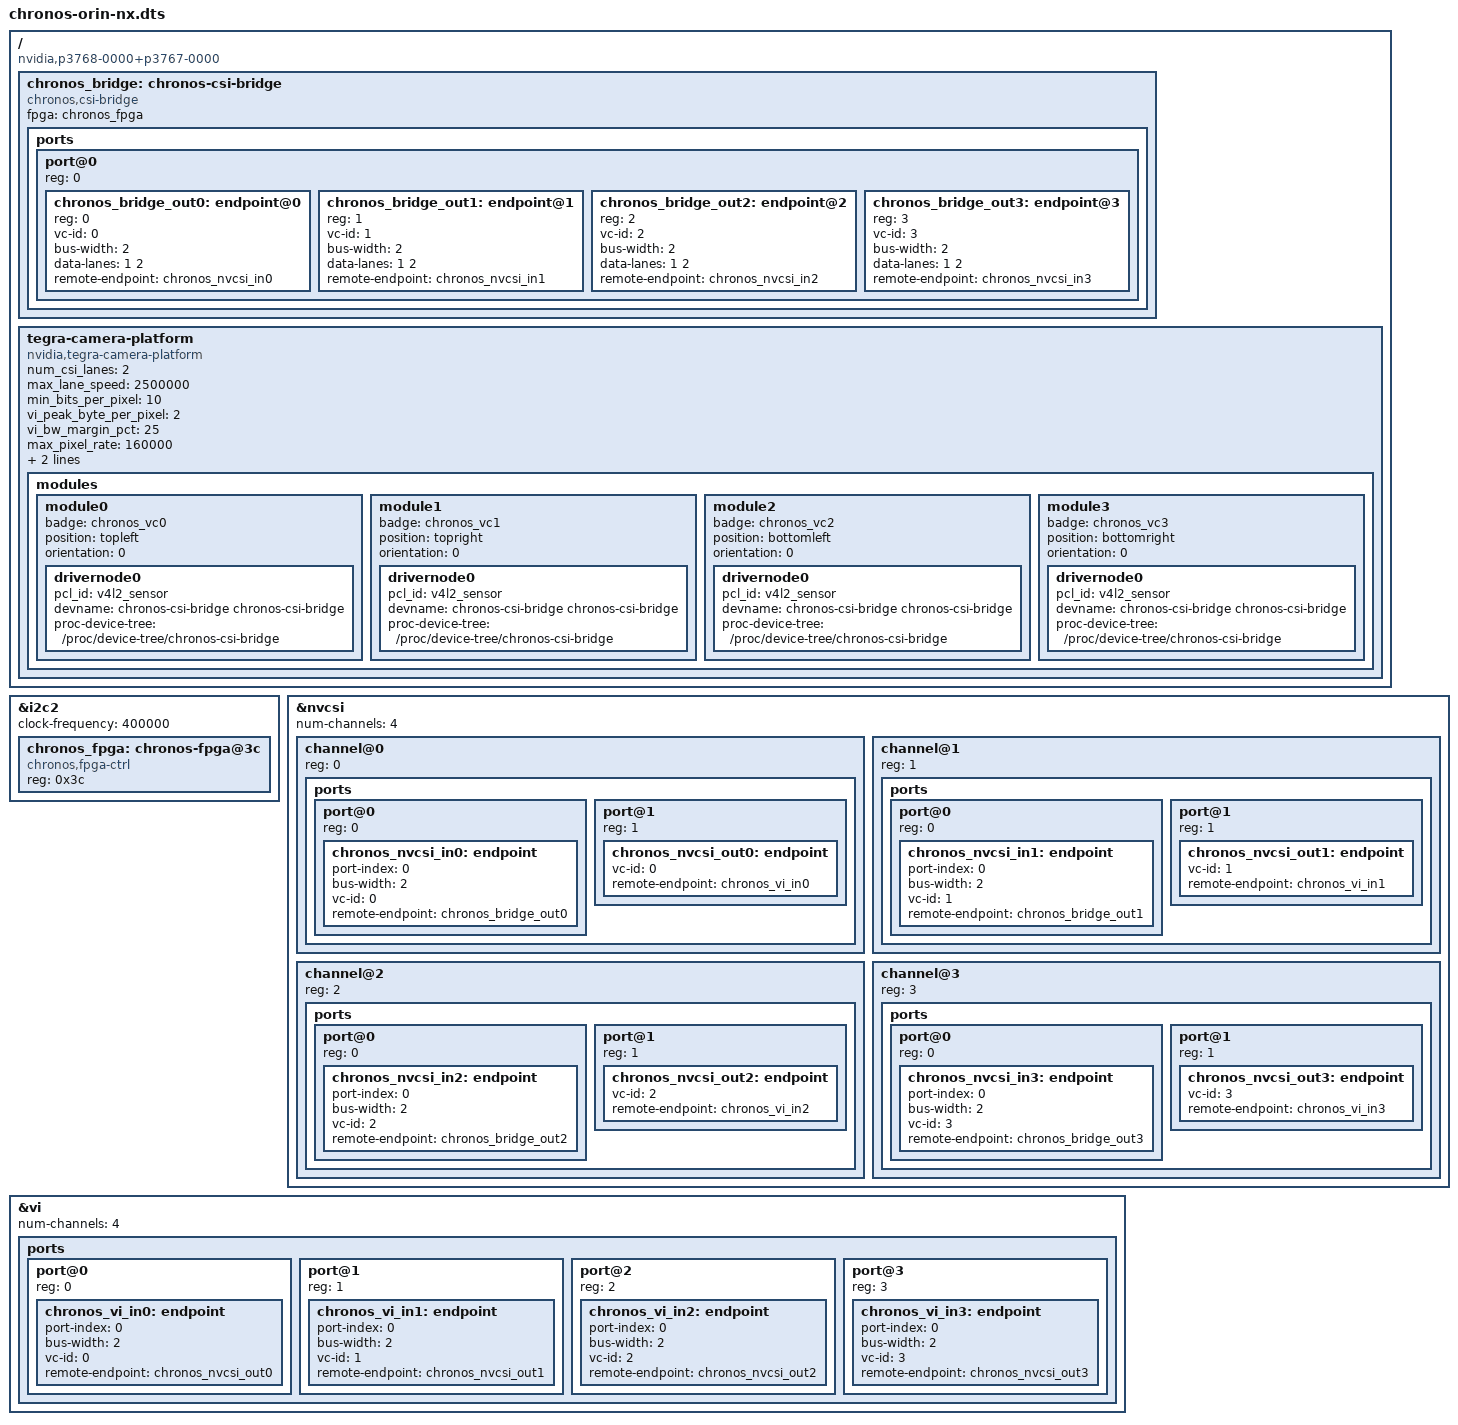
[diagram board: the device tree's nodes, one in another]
// SPDX-License-Identifier: GPL-2.0-only
/*
 * Chronos multi-camera board - device tree overlay for NVIDIA Jetson Orin NX.
 *
 * Board reference : HW_CHRONOS_R1
 *
 * REAL architecture (source of truth: FPGA RTL + board netlist):
 *
 *   - A Lattice CrossLink-NX FPGA aggregates 4x OV9281 cameras into ONE
 *     2-lane MIPI CSI-2 link to the Jetson (connector J7), using virtual
 *     channels VC0..VC3 (VC = camera index).  The Jetson sees exactly one
 *     2-lane CSI source: RAW10 monochrome, 1280x800, 30 fps design point,
 *     frames hardware-triggered by the FPGA FSIN generator.
 *
 *   - The Jetson CANNOT reach the OV9281 sensors over I2C.  The FPGA owns
 *     per-camera private SCCB buses and configures the sensors itself.
 *     There is no I2C mux and there are no sensor nodes in this overlay.
 *
 *   - The FPGA forwards a single on-board 27 MHz oscillator to all four
 *     camera XCLK inputs (the camera modules have no oscillator of their
 *     own).  No clock is modelled on the Jetson side.
 *
 *   - The ICM-42688-P IMU is wired ONLY to the FPGA (SPI + INT).  The
 *     Jetson has no path to it, so it does not appear in this overlay.
 *
 *   - The only Jetson-visible control interface is the FPGA I2C slave at
 *     7-bit address 0x3C (register map in fpga/rtl/config_regs.sv),
 *     handled by the chronos_fpga driver.
 *
 * Driver topology created by this overlay:
 *
 *   chronos_fpga (I2C 0x3C)  <--fpga phandle--  chronos_bridge (subdev)
 *                                                     | x4 endpoints
 *                                             NVCSI channel@0..3
 *                                                     | 1:1
 *                                             VI (4 channels, vc-id 0..3)
 *
 * The Tegra VI creates /dev/video0..3; all four map to the same physical
 * 2-lane NVCSI stream and are demultiplexed by virtual channel (the graph
 * is fanned out 1:1 bridge-endpoint -> NVCSI channel -> VI port because
 * Tegra requires strict endpoint pairing, as in L4T GMSL examples).
 */

/dts-v1/;
/plugin/;

/ {
	compatible = "nvidia,p3768-0000+p3767-0000";  /* Orin NX dev kit */

	/* Host I2C2 -> FPGA control interface (7-bit 0x3C). */
	fragment@0 {
		target = <&i2c2>;
		__overlay__ {
			#address-cells = <1>;
			#size-cells = <0>;
			status = "okay";
			clock-frequency = <400000>;

			chronos_fpga: chronos-fpga@3c {
				compatible = "chronos,fpga-ctrl";
				reg = <0x3c>;
				status = "okay";
			};
		};
	};

	/*
	 * The aggregated CSI-2 source.  One subdev with one source port that
	 * carries FOUR endpoints - one per virtual channel - because Tegra's
	 * multi-VC plumbing (same mechanism as L4T GMSL setups) requires a
	 * strict 1:1 endpoint pairing all the way down the graph:
	 *   bridge endpoint@N  <->  NVCSI channel@N input,
	 *   NVCSI channel@N output  <->  VI port@N.
	 * All four share the SAME physical 2-lane link; only the vc-id
	 * differs.
	 */
	fragment@1 {
		target-path = "/";
		__overlay__ {
			chronos_bridge: chronos-csi-bridge {
				compatible = "chronos,csi-bridge";
				status = "okay";

				fpga = <&chronos_fpga>;

				ports {
					#address-cells = <1>;
					#size-cells = <0>;

					port@0 {
						reg = <0>;
						#address-cells = <1>;
						#size-cells = <0>;

						chronos_bridge_out0: endpoint@0 {
							reg = <0>;
							vc-id = <0>;
							bus-width = <2>;
							data-lanes = <1 2>;
							remote-endpoint = <&chronos_nvcsi_in0>;
						};
						chronos_bridge_out1: endpoint@1 {
							reg = <1>;
							vc-id = <1>;
							bus-width = <2>;
							data-lanes = <1 2>;
							remote-endpoint = <&chronos_nvcsi_in1>;
						};
						chronos_bridge_out2: endpoint@2 {
							reg = <2>;
							vc-id = <2>;
							bus-width = <2>;
							data-lanes = <1 2>;
							remote-endpoint = <&chronos_nvcsi_in2>;
						};
						chronos_bridge_out3: endpoint@3 {
							reg = <3>;
							vc-id = <3>;
							bus-width = <2>;
							data-lanes = <1 2>;
							remote-endpoint = <&chronos_nvcsi_in3>;
						};
					};
				};
			};
		};
	};

	/*
	 * NVCSI: four channels (matching VI num-channels), all on physical
	 * port A / brick 0, one per virtual channel.  Every channel input
	 * pairs 1:1 with a bridge endpoint and every output with a VI port.
	 */
	fragment@2 {
		target = <&nvcsi>;
		__overlay__ {
			status = "okay";
			num-channels = <4>;
			#address-cells = <1>;
			#size-cells = <0>;

			channel@0 {
				reg = <0>;
				status = "okay";

				ports {
					#address-cells = <1>;
					#size-cells = <0>;

					port@0 {
						reg = <0>;
						chronos_nvcsi_in0: endpoint {
							port-index = <0>;
							bus-width = <2>;
							vc-id = <0>;
							remote-endpoint = <&chronos_bridge_out0>;
						};
					};
					port@1 {
						reg = <1>;
						chronos_nvcsi_out0: endpoint {
							vc-id = <0>;
							remote-endpoint = <&chronos_vi_in0>;
						};
					};
				};
			};

			channel@1 {
				reg = <1>;
				status = "okay";

				ports {
					#address-cells = <1>;
					#size-cells = <0>;

					port@0 {
						reg = <0>;
						chronos_nvcsi_in1: endpoint {
							port-index = <0>;
							bus-width = <2>;
							vc-id = <1>;
							remote-endpoint = <&chronos_bridge_out1>;
						};
					};
					port@1 {
						reg = <1>;
						chronos_nvcsi_out1: endpoint {
							vc-id = <1>;
							remote-endpoint = <&chronos_vi_in1>;
						};
					};
				};
			};

			channel@2 {
				reg = <2>;
				status = "okay";

				ports {
					#address-cells = <1>;
					#size-cells = <0>;

					port@0 {
						reg = <0>;
						chronos_nvcsi_in2: endpoint {
							port-index = <0>;
							bus-width = <2>;
							vc-id = <2>;
							remote-endpoint = <&chronos_bridge_out2>;
						};
					};
					port@1 {
						reg = <1>;
						chronos_nvcsi_out2: endpoint {
							vc-id = <2>;
							remote-endpoint = <&chronos_vi_in2>;
						};
					};
				};
			};

			channel@3 {
				reg = <3>;
				status = "okay";

				ports {
					#address-cells = <1>;
					#size-cells = <0>;

					port@0 {
						reg = <0>;
						chronos_nvcsi_in3: endpoint {
							port-index = <0>;
							bus-width = <2>;
							vc-id = <3>;
							remote-endpoint = <&chronos_bridge_out3>;
						};
					};
					port@1 {
						reg = <1>;
						chronos_nvcsi_out3: endpoint {
							vc-id = <3>;
							remote-endpoint = <&chronos_vi_in3>;
						};
					};
				};
			};
		};
	};

	/*
	 * VI: four channels, all mapped to the SAME NVCSI physical stream,
	 * selected by CSI-2 virtual channel via the "vc-id" endpoint property
	 * (same mechanism L4T uses for multi-VC GMSL setups).  VC = camera
	 * index.  VI allocates capture buffers from CMA; no reserved-memory
	 * carveout is needed.
	 */
	fragment@3 {
		target = <&vi>;
		__overlay__ {
			status = "okay";
			num-channels = <4>;

			ports {
				#address-cells = <1>;
				#size-cells = <0>;

				port@0 {
					reg = <0>;
					chronos_vi_in0: endpoint {
						port-index = <0>;
						bus-width = <2>;
						vc-id = <0>;
						remote-endpoint = <&chronos_nvcsi_out0>;
					};
				};
				port@1 {
					reg = <1>;
					chronos_vi_in1: endpoint {
						port-index = <0>;
						bus-width = <2>;
						vc-id = <1>;
						remote-endpoint = <&chronos_nvcsi_out1>;
					};
				};
				port@2 {
					reg = <2>;
					chronos_vi_in2: endpoint {
						port-index = <0>;
						bus-width = <2>;
						vc-id = <2>;
						remote-endpoint = <&chronos_nvcsi_out2>;
					};
				};
				port@3 {
					reg = <3>;
					chronos_vi_in3: endpoint {
						port-index = <0>;
						bus-width = <2>;
						vc-id = <3>;
						remote-endpoint = <&chronos_nvcsi_out3>;
					};
				};
			};
		};
	};

	/*
	 * tegra-camera-platform: one module entry per virtual channel so the
	 * Tegra camera framework sizes clocks/bandwidth for four streams.
	 *
	 * Entries are intentionally minimal and honest: the "sensor" of this
	 * graph is the Chronos bridge (there are no Jetson-visible OV9281
	 * devices).  Argus/nvarguscamerasrc additionally requires per-mode
	 * tables (mode0 { ... }) matching the sensor timing before it will
	 * use these modules; V4L2 capture via v4l2-ctl works without them.
	 *
	 * NOTE: drivernode0 must reference the V4L2 subdev that sources the
	 * stream - the chronos_csi BRIDGE - not the FPGA I2C control device
	 * (which is not a subdev).  The subdev name is built in chronos_csi.c
	 * as "chronos-csi-bridge <dev_name>"; for this root-level DT node the
	 * platform dev_name is "chronos-csi-bridge".  Verify the exact
	 * runtime name with `media-ctl -p` after first probe and adjust here
	 * if it differs.
	 */
	fragment@4 {
		target-path = "/";
		__overlay__ {
			tegra-camera-platform {
				compatible = "nvidia,tegra-camera-platform";
				num_csi_lanes = <2>;
				max_lane_speed = <2500000>;	/* kbps per lane */
				min_bits_per_pixel = <10>;
				vi_peak_byte_per_pixel = <2>;
				vi_bw_margin_pct = <25>;
				max_pixel_rate = <160000>;	/* 4 x 1280x800 @ 30fps, kpix/s */
				isp_peak_byte_per_pixel = <2>;
				isp_bw_margin_pct = <25>;

				modules {
					module0 {
						badge = "chronos_vc0";
						position = "topleft";
						orientation = "0";
						drivernode0 {
							pcl_id = "v4l2_sensor";
							devname = "chronos-csi-bridge chronos-csi-bridge";
							proc-device-tree = "/proc/device-tree/chronos-csi-bridge";
						};
					};
					module1 {
						badge = "chronos_vc1";
						position = "topright";
						orientation = "0";
						drivernode0 {
							pcl_id = "v4l2_sensor";
							devname = "chronos-csi-bridge chronos-csi-bridge";
							proc-device-tree = "/proc/device-tree/chronos-csi-bridge";
						};
					};
					module2 {
						badge = "chronos_vc2";
						position = "bottomleft";
						orientation = "0";
						drivernode0 {
							pcl_id = "v4l2_sensor";
							devname = "chronos-csi-bridge chronos-csi-bridge";
							proc-device-tree = "/proc/device-tree/chronos-csi-bridge";
						};
					};
					module3 {
						badge = "chronos_vc3";
						position = "bottomright";
						orientation = "0";
						drivernode0 {
							pcl_id = "v4l2_sensor";
							devname = "chronos-csi-bridge chronos-csi-bridge";
							proc-device-tree = "/proc/device-tree/chronos-csi-bridge";
						};
					};
				};
			};
		};
	};
};
